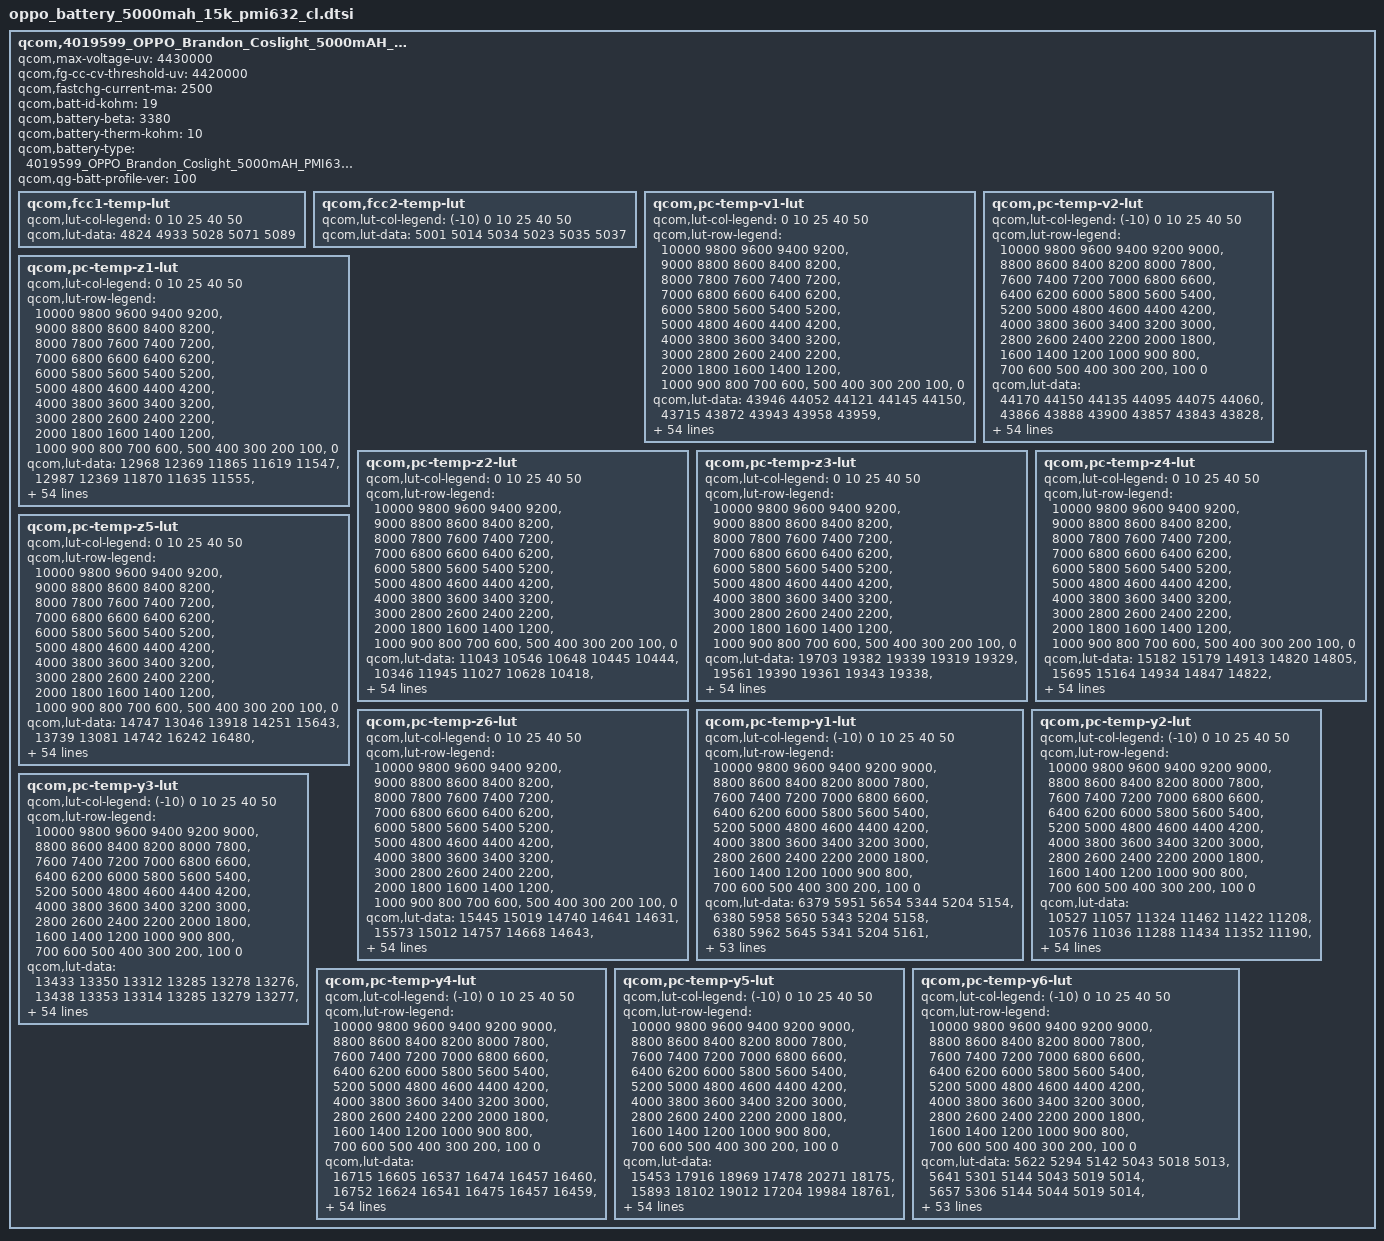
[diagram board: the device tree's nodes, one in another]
qcom,4019599_OPPO_Brandon_Coslight_5000mAH_PMI632 {
    /* 4019599_OPPO_Brandon_Coslight_5000mAH_PMI632_averaged_MasterSlave_Jun21th2019 */
    qcom,max-voltage-uv = <4430000>;
    qcom,fg-cc-cv-threshold-uv = <4420000>;
    qcom,fastchg-current-ma = <2500>;
    qcom,batt-id-kohm = <19>;
    qcom,battery-beta = <3380>;
    qcom,battery-therm-kohm = <10>;
    qcom,battery-type = "4019599_OPPO_Brandon_Coslight_5000mAH_PMI632_averaged_MasterSlave_Jun21th2019";
    qcom,qg-batt-profile-ver = <100>;

	qcom,fcc1-temp-lut {
		qcom,lut-col-legend = <0 10 25 40 50>;
		qcom,lut-data = <4824 4933 5028 5071 5089>;
	};

	qcom,fcc2-temp-lut {
		qcom,lut-col-legend = <(-10) 0 10 25 40 50>;
		qcom,lut-data = <5001 5014 5034 5023 5035 5037>;
	};

	qcom,pc-temp-v1-lut {
		qcom,lut-col-legend = <0 10 25 40 50>;
		qcom,lut-row-legend = <10000 9800 9600 9400 9200>,
			<9000 8800 8600 8400 8200>,
			<8000 7800 7600 7400 7200>,
			<7000 6800 6600 6400 6200>,
			<6000 5800 5600 5400 5200>,
			<5000 4800 4600 4400 4200>,
			<4000 3800 3600 3400 3200>,
			<3000 2800 2600 2400 2200>,
			<2000 1800 1600 1400 1200>,
			<1000 900 800 700 600>,
			<500 400 300 200 100>,
			<0>;
		qcom,lut-data = <43946 44052 44121 44145 44150>,
			<43715 43872 43943 43958 43959>,
			<43484 43673 43752 43763 43765>,
			<43250 43452 43548 43560 43565>,
			<43015 43216 43324 43348 43354>,
			<42775 42973 43088 43129 43132>,
			<42537 42718 42849 42899 42904>,
			<42298 42468 42605 42658 42669>,
			<42062 42232 42362 42413 42431>,
			<41833 42001 42123 42174 42194>,
			<41609 41771 41888 41938 41957>,
			<41391 41540 41655 41705 41722>,
			<41177 41317 41426 41475 41491>,
			<40969 41107 41204 41250 41263>,
			<40760 40903 40987 41033 41042>,
			<40548 40699 40778 40823 40827>,
			<40345 40492 40580 40620 40622>,
			<40167 40294 40389 40425 40426>,
			<40006 40115 40203 40234 40237>,
			<39846 39944 40027 40055 40059>,
			<39680 39762 39839 39875 39884>,
			<39513 39564 39583 39652 39672>,
			<39348 39362 39287 39374 39403>,
			<39181 39143 39087 39151 39172>,
			<39019 38923 38965 39011 39020>,
			<38857 38775 38862 38897 38896>,
			<38704 38684 38756 38778 38775>,
			<38593 38609 38654 38661 38661>,
			<38516 38532 38558 38556 38557>,
			<38453 38460 38465 38461 38460>,
			<38398 38394 38382 38375 38371>,
			<38350 38331 38308 38297 38290>,
			<38307 38275 38242 38225 38216>,
			<38269 38225 38182 38158 38145>,
			<38234 38181 38131 38096 38073>,
			<38198 38138 38081 38036 38002>,
			<38163 38097 38032 37975 37933>,
			<38120 38051 37983 37915 37863>,
			<38052 37984 37915 37840 37781>,
			<37961 37888 37820 37742 37680>,
			<37858 37780 37710 37630 37567>,
			<37736 37659 37591 37510 37443>,
			<37595 37521 37456 37376 37306>,
			<37427 37356 37298 37220 37149>,
			<37289 37220 37160 37092 37027>,
			<37195 37130 37070 37011 36954>,
			<37171 37106 37048 36984 36930>,
			<37137 37083 37027 36969 36911>,
			<37101 37053 37006 36940 36878>,
			<37019 36969 36905 36825 36734>,
			<36720 36657 36579 36489 36394>,
			<36255 36195 36124 36023 35934>,
			<35654 35595 35529 35431 35343>,
			<34825 34767 34715 34627 34529>,
			<33466 33434 33438 33348 33254>,
			<30000 30000 30000 30000 30000>;
	};

	qcom,pc-temp-v2-lut {
		qcom,lut-col-legend = <(-10) 0 10 25 40 50>;
		qcom,lut-row-legend = <10000 9800 9600 9400 9200 9000>,
			<8800 8600 8400 8200 8000 7800>,
			<7600 7400 7200 7000 6800 6600>,
			<6400 6200 6000 5800 5600 5400>,
			<5200 5000 4800 4600 4400 4200>,
			<4000 3800 3600 3400 3200 3000>,
			<2800 2600 2400 2200 2000 1800>,
			<1600 1400 1200 1000 900 800>,
			<700 600 500 400 300 200>,
			<100 0>;
		qcom,lut-data = <44170 44150 44135 44095 44075 44060>,
			<43866 43888 43900 43857 43843 43828>,
			<43585 43635 43668 43623 43613 43600>,
			<43329 43394 43441 43394 43388 43375>,
			<43100 43167 43219 43170 43167 43156>,
			<42872 42937 42991 42942 42942 42932>,
			<42631 42698 42753 42704 42706 42698>,
			<42387 42456 42510 42463 42466 42459>,
			<42143 42215 42269 42224 42227 42221>,
			<41901 41975 42028 41986 41988 41983>,
			<41652 41740 41791 41752 41753 41749>,
			<41381 41513 41557 41519 41520 41517>,
			<41110 41291 41326 41291 41292 41289>,
			<40889 41066 41102 41069 41071 41067>,
			<40712 40843 40883 40852 40854 40849>,
			<40512 40613 40666 40642 40645 40639>,
			<40219 40364 40451 40439 40442 40437>,
			<39897 40111 40233 40241 40244 40243>,
			<39663 39874 39997 40046 40057 40058>,
			<39489 39648 39746 39856 39879 39882>,
			<39321 39437 39513 39650 39681 39685>,
			<39140 39243 39306 39398 39425 39428>,
			<38960 39063 39117 39145 39170 39171>,
			<38793 38900 38950 38958 38982 38986>,
			<38636 38752 38798 38806 38830 38836>,
			<38486 38616 38662 38674 38695 38703>,
			<38333 38490 38539 38554 38573 38581>,
			<38193 38373 38427 38446 38463 38470>,
			<38097 38255 38324 38345 38363 38367>,
			<38029 38140 38227 38251 38271 38270>,
			<37968 38040 38136 38164 38187 38184>,
			<37909 37958 38050 38085 38112 38109>,
			<37853 37889 37970 38011 38039 38035>,
			<37794 37834 37892 37940 37963 37956>,
			<37733 37790 37817 37872 37884 37873>,
			<37669 37746 37753 37798 37796 37777>,
			<37600 37700 37703 37715 37688 37657>,
			<37527 37650 37653 37627 37578 37537>,
			<37448 37588 37588 37544 37484 37439>,
			<37361 37513 37512 37463 37396 37352>,
			<37273 37418 37425 37375 37305 37259>,
			<37185 37280 37320 37274 37212 37161>,
			<37099 37136 37197 37161 37102 37048>,
			<37016 37009 37051 37028 36966 36912>,
			<36925 36903 36933 36913 36866 36811>,
			<36821 36822 36861 36867 36828 36782>,
			<36759 36778 36836 36852 36813 36767>,
			<36687 36730 36806 36829 36796 36746>,
			<36584 36650 36754 36789 36753 36695>,
			<36439 36513 36630 36666 36585 36503>,
			<36212 36253 36329 36331 36211 36113>,
			<35837 35807 35826 35823 35695 35590>,
			<35270 35191 35135 35171 35021 34905>,
			<34453 34314 34209 34274 34083 33956>,
			<33093 32831 32728 32846 32678 32536>,
			<29714 27670 27572 27625 27714 27673>;
	};

	qcom,pc-temp-z1-lut {
		qcom,lut-col-legend = <0 10 25 40 50>;
		qcom,lut-row-legend = <10000 9800 9600 9400 9200>,
			<9000 8800 8600 8400 8200>,
			<8000 7800 7600 7400 7200>,
			<7000 6800 6600 6400 6200>,
			<6000 5800 5600 5400 5200>,
			<5000 4800 4600 4400 4200>,
			<4000 3800 3600 3400 3200>,
			<3000 2800 2600 2400 2200>,
			<2000 1800 1600 1400 1200>,
			<1000 900 800 700 600>,
			<500 400 300 200 100>,
			<0>;
		qcom,lut-data = <12968 12369 11865 11619 11547>,
			<12987 12369 11870 11635 11555>,
			<12980 12366 11871 11632 11555>,
			<12970 12360 11870 11630 11555>,
			<12959 12352 11862 11628 11554>,
			<12941 12341 11853 11627 11554>,
			<12928 12326 11846 11626 11554>,
			<12923 12310 11839 11624 11555>,
			<12917 12295 11834 11623 11558>,
			<12905 12281 11831 11624 11561>,
			<12872 12270 11829 11627 11565>,
			<12844 12262 11828 11628 11567>,
			<12835 12257 11827 11627 11566>,
			<12829 12255 11826 11626 11565>,
			<12822 12252 11825 11625 11565>,
			<12799 12249 11825 11625 11565>,
			<12775 12244 11825 11624 11565>,
			<12770 12241 11827 11625 11565>,
			<12768 12242 11829 11625 11566>,
			<12768 12245 11831 11625 11566>,
			<12774 12247 11833 11625 11567>,
			<12783 12248 11834 11626 11567>,
			<12787 12250 11836 11628 11567>,
			<12790 12253 11838 11630 11568>,
			<12792 12258 11842 11632 11569>,
			<12801 12262 11846 11634 11572>,
			<12816 12265 11850 11637 11575>,
			<12820 12268 11855 11640 11578>,
			<12813 12273 11859 11643 11582>,
			<12807 12278 11863 11646 11584>,
			<12813 12284 11867 11649 11585>,
			<12827 12291 11872 11652 11588>,
			<12834 12298 11878 11656 11591>,
			<12831 12303 11883 11659 11594>,
			<12827 12306 11888 11663 11597>,
			<12830 12310 11893 11667 11600>,
			<12837 12314 11898 11670 11603>,
			<12846 12319 11904 11673 11606>,
			<12862 12326 11909 11676 11608>,
			<12880 12336 11913 11680 11611>,
			<12890 12346 11918 11683 11614>,
			<12899 12354 11923 11687 11617>,
			<12905 12362 11930 11690 11620>,
			<12914 12369 11939 11693 11621>,
			<12928 12384 11948 11697 11623>,
			<12938 12392 11952 11699 11624>,
			<12936 12381 11956 11700 11625>,
			<12934 12390 11955 11700 11626>,
			<12925 12390 11964 11704 11629>,
			<12948 12411 11965 11708 11631>,
			<12981 12410 11977 11712 11635>,
			<12976 12423 11982 11719 11641>,
			<12970 12448 11997 11728 11649>,
			<13013 12475 12016 11742 11661>,
			<13013 12475 12016 11742 11661>,
			<13013 12475 12016 11742 11661>;
	};

	qcom,pc-temp-z2-lut {
		qcom,lut-col-legend = <0 10 25 40 50>;
		qcom,lut-row-legend = <10000 9800 9600 9400 9200>,
			<9000 8800 8600 8400 8200>,
			<8000 7800 7600 7400 7200>,
			<7000 6800 6600 6400 6200>,
			<6000 5800 5600 5400 5200>,
			<5000 4800 4600 4400 4200>,
			<4000 3800 3600 3400 3200>,
			<3000 2800 2600 2400 2200>,
			<2000 1800 1600 1400 1200>,
			<1000 900 800 700 600>,
			<500 400 300 200 100>,
			<0>;
		qcom,lut-data = <11043 10546 10648 10445 10444>,
			<10346 11945 11027 10628 10418>,
			<10349 12454 11980 10634 10484>,
			<10352 12098 12380 10641 10576>,
			<10347 11505 12147 11047 10589>,
			<10328 11057 11804 11998 10572>,
			<10312 10637 11506 12224 10551>,
			<10306 10441 11162 11325 10508>,
			<10302 10513 11020 10549 10456>,
			<10313 10619 11161 10701 10405>,
			<10385 10605 11345 11094 10332>,
			<10437 10477 11401 11329 10301>,
			<10391 10398 11449 11832 10302>,
			<10299 10579 11503 12180 10308>,
			<10262 10880 11584 12140 10312>,
			<10255 10914 11643 12067 10318>,
			<10250 10678 11632 12072 10328>,
			<10314 10499 11578 12194 10356>,
			<10534 10503 11471 12274 10386>,
			<10653 10519 11049 11634 10409>,
			<10531 10537 10685 10661 10434>,
			<10357 10562 10694 10512 10462>,
			<10325 10584 10749 10599 10492>,
			<10344 10596 10762 10649 10523>,
			<10368 10605 10705 10618 10686>,
			<10388 10606 10654 10578 10907>,
			<10407 10592 10672 10612 10919>,
			<10414 10578 10716 10757 10773>,
			<10414 10579 10734 10825 10648>,
			<10413 10581 10740 10736 10543>,
			<10414 10583 10742 10613 10439>,
			<10417 10582 10728 10552 10388>,
			<10420 10582 10699 10507 10350>,
			<10423 10585 10694 10496 10338>,
			<10427 10593 10717 10543 10363>,
			<10429 10596 10746 10607 10406>,
			<10430 10600 10769 10652 10465>,
			<10432 10606 10793 10696 10557>,
			<10438 10614 10812 10734 10625>,
			<10446 10631 10829 10826 10668>,
			<10448 10638 10841 10901 10712>,
			<10446 10627 10847 10900 10786>,
			<10446 10619 10849 10889 10861>,
			<10466 10632 10854 10885 10877>,
			<10690 10731 10866 10822 10801>,
			<10709 10785 10893 10723 10604>,
			<10704 10809 10835 10696 10623>,
			<10694 10820 10810 10702 10643>,
			<10640 10972 10815 10803 10727>,
			<10683 11011 10892 10825 10696>,
			<10558 10879 10869 10623 10424>,
			<10392 10853 10839 10482 10331>,
			<10188 10697 10793 10416 10271>,
			<9984 10462 10693 11606 10223>,
			<9984 10462 10693 11606 10223>,
			<9984 10462 10693 11606 10223>;
	};

	qcom,pc-temp-z3-lut {
		qcom,lut-col-legend = <0 10 25 40 50>;
		qcom,lut-row-legend = <10000 9800 9600 9400 9200>,
			<9000 8800 8600 8400 8200>,
			<8000 7800 7600 7400 7200>,
			<7000 6800 6600 6400 6200>,
			<6000 5800 5600 5400 5200>,
			<5000 4800 4600 4400 4200>,
			<4000 3800 3600 3400 3200>,
			<3000 2800 2600 2400 2200>,
			<2000 1800 1600 1400 1200>,
			<1000 900 800 700 600>,
			<500 400 300 200 100>,
			<0>;
		qcom,lut-data = <19703 19382 19339 19319 19329>,
			<19561 19390 19361 19343 19338>,
			<19607 19406 19374 19358 19353>,
			<19663 19446 19389 19374 19364>,
			<19676 19495 19417 19390 19372>,
			<19680 19519 19440 19406 19379>,
			<19683 19534 19446 19410 19382>,
			<19685 19543 19445 19402 19383>,
			<19687 19547 19447 19394 19384>,
			<19691 19547 19458 19397 19383>,
			<19706 19541 19469 19405 19380>,
			<19716 19525 19469 19409 19376>,
			<19702 19515 19464 19414 19374>,
			<19674 19527 19459 19417 19372>,
			<19664 19547 19455 19411 19369>,
			<19664 19547 19450 19403 19367>,
			<19666 19513 19443 19397 19364>,
			<19670 19487 19435 19394 19360>,
			<19682 19487 19425 19390 19355>,
			<19688 19489 19409 19374 19350>,
			<19670 19491 19397 19356 19345>,
			<19645 19499 19402 19353 19344>,
			<19641 19508 19416 19357 19344>,
			<19644 19512 19419 19359 19345>,
			<19649 19516 19402 19349 19356>,
			<19653 19517 19387 19337 19372>,
			<19658 19509 19387 19346 19378>,
			<19659 19500 19390 19381 19389>,
			<19653 19499 19395 19398 19394>,
			<19645 19498 19409 19395 19388>,
			<19639 19498 19419 19388 19379>,
			<19634 19499 19419 19383 19371>,
			<19630 19501 19418 19376 19363>,
			<19626 19500 19416 19370 19357>,
			<19624 19498 19412 19364 19352>,
			<19620 19496 19407 19358 19348>,
			<19617 19494 19403 19355 19345>,
			<19613 19491 19399 19352 19342>,
			<19609 19487 19397 19351 19342>,
			<19605 19483 19395 19352 19342>,
			<19598 19479 19393 19352 19342>,
			<19588 19475 19391 19354 19346>,
			<19577 19471 19389 19356 19352>,
			<19566 19465 19385 19356 19354>,
			<19495 19439 19376 19350 19349>,
			<19442 19419 19369 19337 19334>,
			<19330 19390 19361 19336 19325>,
			<19320 19347 19360 19327 19322>,
			<19312 19327 19344 19324 19317>,
			<19303 19324 19340 19327 19329>,
			<19321 19330 19353 19350 19345>,
			<19322 19327 19341 19350 19346>,
			<19334 19324 19343 19346 19342>,
			<19341 19322 19343 19261 19343>,
			<19341 19322 19343 19261 19343>,
			<19341 19322 19343 19261 19343>;
	};

	qcom,pc-temp-z4-lut {
		qcom,lut-col-legend = <0 10 25 40 50>;
		qcom,lut-row-legend = <10000 9800 9600 9400 9200>,
			<9000 8800 8600 8400 8200>,
			<8000 7800 7600 7400 7200>,
			<7000 6800 6600 6400 6200>,
			<6000 5800 5600 5400 5200>,
			<5000 4800 4600 4400 4200>,
			<4000 3800 3600 3400 3200>,
			<3000 2800 2600 2400 2200>,
			<2000 1800 1600 1400 1200>,
			<1000 900 800 700 600>,
			<500 400 300 200 100>,
			<0>;
		qcom,lut-data = <15182 15179 14913 14820 14805>,
			<15695 15164 14934 14847 14822>,
			<15608 15134 14904 14840 14816>,
			<15472 15068 14871 14826 14806>,
			<15365 14986 14829 14796 14794>,
			<15267 14938 14789 14749 14777>,
			<15181 14905 14770 14734 14762>,
			<15114 14873 14755 14737 14749>,
			<15054 14832 14741 14739 14736>,
			<14993 14795 14709 14725 14723>,
			<14922 14783 14676 14692 14711>,
			<14876 14782 14661 14672 14703>,
			<14867 14777 14651 14651 14698>,
			<14865 14738 14646 14639 14694>,
			<14858 14684 14642 14639 14690>,
			<14844 14678 14641 14639 14686>,
			<14824 14716 14641 14639 14683>,
			<14790 14744 14643 14636 14680>,
			<14734 14737 14647 14634 14678>,
			<14707 14722 14662 14645 14679>,
			<14724 14719 14684 14670 14680>,
			<14752 14726 14726 14707 14691>,
			<14767 14738 14786 14769 14753>,
			<14774 14767 14807 14801 14795>,
			<14783 14811 14809 14802 14778>,
			<14802 14824 14811 14803 14750>,
			<14826 14817 14804 14790 14733>,
			<14833 14807 14785 14739 14709>,
			<14832 14797 14765 14707 14694>,
			<14831 14785 14741 14700 14691>,
			<14828 14774 14722 14695 14689>,
			<14821 14764 14714 14692 14686>,
			<14813 14756 14709 14688 14683>,
			<14804 14749 14707 14687 14681>,
			<14796 14744 14705 14688 14681>,
			<14787 14740 14705 14688 14681>,
			<14778 14736 14705 14689 14681>,
			<14769 14734 14706 14689 14683>,
			<14761 14732 14708 14691 14685>,
			<14753 14731 14712 14697 14692>,
			<14745 14729 14714 14702 14698>,
			<14738 14719 14709 14697 14692>,
			<14727 14706 14698 14689 14683>,
			<14711 14696 14693 14688 14683>,
			<14697 14674 14675 14681 14677>,
			<14733 14663 14654 14663 14661>,
			<14853 14684 14650 14655 14658>,
			<14861 14727 14642 14647 14644>,
			<14864 14742 14647 14634 14629>,
			<14861 14741 14653 14636 14632>,
			<14848 14747 14659 14644 14648>,
			<14863 14757 14677 14650 14653>,
			<14863 14768 14675 14655 14659>,
			<14878 14783 14679 14746 14657>,
			<14878 14783 14679 14746 14657>,
			<14878 14783 14679 14746 14657>;
	};

	qcom,pc-temp-z5-lut {
		qcom,lut-col-legend = <0 10 25 40 50>;
		qcom,lut-row-legend = <10000 9800 9600 9400 9200>,
			<9000 8800 8600 8400 8200>,
			<8000 7800 7600 7400 7200>,
			<7000 6800 6600 6400 6200>,
			<6000 5800 5600 5400 5200>,
			<5000 4800 4600 4400 4200>,
			<4000 3800 3600 3400 3200>,
			<3000 2800 2600 2400 2200>,
			<2000 1800 1600 1400 1200>,
			<1000 900 800 700 600>,
			<500 400 300 200 100>,
			<0>;
		qcom,lut-data = <14747 13046 13918 14251 15643>,
			<13739 13081 14742 16242 16480>,
			<14343 13234 15031 17518 18075>,
			<15181 13918 15551 18938 19444>,
			<15594 15096 17205 20465 20449>,
			<15831 16409 19129 22101 21269>,
			<16112 18109 20216 22520 21866>,
			<16535 19401 21159 22062 22257>,
			<17094 20261 22461 21669 22601>,
			<17928 20930 25995 23588 23059>,
			<19476 20968 30452 28286 23594>,
			<20581 20578 34018 32056 24063>,
			<20433 20548 37307 38700 24546>,
			<19907 25177 39480 43009 25081>,
			<19913 32451 41064 41381 25842>,
			<20941 33192 41956 38515 26787>,
			<22642 27204 40945 38143 27209>,
			<25393 22670 37677 39571 27272>,
			<29891 23320 34232 40498 27217>,
			<32107 25281 29871 34881 26844>,
			<31676 28204 26887 26279 26064>,
			<31030 34370 29931 24629 25179>,
			<31614 39414 37294 24605 23548>,
			<36109 40714 38899 24456 22133>,
			<40913 41472 29877 21106 21934>,
			<44042 41201 21606 16862 22293>,
			<46601 35906 20807 17654 22957>,
			<47039 30746 20478 22713 25895>,
			<44078 30020 20727 25786 27583>,
			<40407 29720 23948 26609 27546>,
			<38406 29733 27880 27184 27490>,
			<36856 31258 30653 27614 27341>,
			<36178 33344 33109 28200 26979>,
			<36028 34801 34710 28570 26884>,
			<35966 36165 35959 28873 27574>,
			<36053 37192 36581 29142 28396>,
			<36444 38011 36179 29228 28673>,
			<37025 38571 35176 29132 28804>,
			<38260 38621 34125 28828 28670>,
			<39831 38271 32729 27772 26890>,
			<39815 37826 31745 26812 25241>,
			<36187 36946 31528 27037 26564>,
			<34724 36205 31335 27649 29243>,
			<35787 36404 30143 27777 30159>,
			<29211 34744 31201 26716 29293>,
			<22775 30477 33608 24077 23600>,
			<12679 20312 29073 24696 20833>,
			<12408 14903 30020 23109 22284>,
			<12217 13751 22940 26366 26202>,
			<12124 13783 20885 25791 37630>,
			<12577 14052 21736 28003 27786>,
			<12385 13576 17557 24368 24075>,
			<12447 13207 17223 20864 20207>,
			<12307 12896 16508 11789 18636>,
			<12307 12896 16508 11789 18636>,
			<12307 12896 16508 11789 18636>;
	};

	qcom,pc-temp-z6-lut {
		qcom,lut-col-legend = <0 10 25 40 50>;
		qcom,lut-row-legend = <10000 9800 9600 9400 9200>,
			<9000 8800 8600 8400 8200>,
			<8000 7800 7600 7400 7200>,
			<7000 6800 6600 6400 6200>,
			<6000 5800 5600 5400 5200>,
			<5000 4800 4600 4400 4200>,
			<4000 3800 3600 3400 3200>,
			<3000 2800 2600 2400 2200>,
			<2000 1800 1600 1400 1200>,
			<1000 900 800 700 600>,
			<500 400 300 200 100>,
			<0>;
		qcom,lut-data = <15445 15019 14740 14641 14631>,
			<15573 15012 14757 14668 14643>,
			<15540 15002 14753 14672 14649>,
			<15487 14987 14748 14676 14652>,
			<15437 14969 14743 14673 14651>,
			<15382 14954 14737 14664 14648>,
			<15333 14940 14730 14658 14644>,
			<15294 14926 14722 14655 14640>,
			<15259 14907 14714 14651 14635>,
			<15229 14888 14706 14645 14629>,
			<15202 14874 14699 14638 14623>,
			<15178 14863 14691 14633 14618>,
			<15157 14852 14685 14628 14615>,
			<15138 14841 14679 14623 14611>,
			<15122 14830 14675 14619 14608>,
			<15110 14824 14672 14615 14605>,
			<15099 14821 14668 14611 14601>,
			<15085 14819 14664 14607 14598>,
			<15067 14815 14662 14605 14594>,
			<15059 14811 14662 14604 14592>,
			<15060 14811 14662 14603 14589>,
			<15060 14818 14678 14610 14593>,
			<15062 14829 14714 14640 14620>,
			<15069 14846 14726 14657 14639>,
			<15078 14867 14721 14654 14638>,
			<15091 14873 14714 14650 14635>,
			<15106 14868 14709 14646 14633>,
			<15110 14861 14705 14644 14629>,
			<15108 14856 14701 14641 14625>,
			<15104 14852 14699 14637 14621>,
			<15101 14849 14696 14632 14616>,
			<15097 14847 14694 14628 14611>,
			<15093 14845 14691 14623 14606>,
			<15090 14843 14689 14620 14602>,
			<15087 14842 14688 14617 14598>,
			<15084 14841 14686 14615 14596>,
			<15082 14840 14685 14613 14595>,
			<15081 14839 14684 14612 14594>,
			<15081 14839 14684 14612 14594>,
			<15081 14840 14686 14615 14597>,
			<15081 14839 14687 14618 14600>,
			<15079 14837 14685 14617 14600>,
			<15077 14833 14681 14615 14600>,
			<15074 14830 14678 14615 14601>,
			<15049 14815 14669 14610 14596>,
			<15041 14804 14657 14595 14581>,
			<15036 14799 14652 14592 14576>,
			<15035 14796 14648 14583 14568>,
			<15034 14795 14643 14576 14558>,
			<15035 14796 14645 14579 14566>,
			<15045 14807 14657 14596 14583>,
			<15061 14814 14660 14600 14588>,
			<15078 14826 14665 14603 14591>,
			<15107 14845 14671 14605 14594>,
			<15107 14845 14671 14605 14594>,
			<15107 14845 14671 14605 14594>;
	};

	qcom,pc-temp-y1-lut {
		qcom,lut-col-legend = <(-10) 0 10 25 40 50>;
		qcom,lut-row-legend = <10000 9800 9600 9400 9200 9000>,
			<8800 8600 8400 8200 8000 7800>,
			<7600 7400 7200 7000 6800 6600>,
			<6400 6200 6000 5800 5600 5400>,
			<5200 5000 4800 4600 4400 4200>,
			<4000 3800 3600 3400 3200 3000>,
			<2800 2600 2400 2200 2000 1800>,
			<1600 1400 1200 1000 900 800>,
			<700 600 500 400 300 200>,
			<100 0>;
		qcom,lut-data = <6379 5951 5654 5344 5204 5154>,
			<6380 5958 5650 5343 5204 5158>,
			<6380 5962 5645 5341 5204 5161>,
			<6380 5963 5641 5339 5203 5162>,
			<6380 5962 5636 5338 5203 5163>,
			<6379 5960 5631 5337 5202 5162>,
			<6377 5954 5625 5334 5200 5161>,
			<6373 5947 5620 5331 5199 5158>,
			<6376 5945 5617 5329 5197 5157>,
			<6394 5940 5615 5328 5196 5156>,
			<6405 5938 5613 5326 5195 5155>,
			<6396 5938 5609 5325 5193 5155>,
			<6381 5939 5605 5324 5191 5155>,
			<6379 5940 5603 5324 5191 5156>,
			<6387 5945 5603 5324 5192 5157>,
			<6394 5948 5602 5324 5193 5157>,
			<6402 5947 5603 5324 5193 5156>,
			<6408 5946 5604 5323 5194 5155>,
			<6408 5947 5605 5323 5194 5155>,
			<6403 5950 5604 5324 5194 5155>,
			<6400 5951 5604 5325 5194 5155>,
			<6403 5948 5603 5327 5195 5156>,
			<6408 5942 5601 5329 5196 5156>,
			<6404 5943 5601 5331 5196 5157>,
			<6387 5950 5603 5334 5197 5158>,
			<6377 5955 5605 5337 5198 5159>,
			<6398 5956 5611 5339 5200 5160>,
			<6429 5957 5618 5342 5203 5161>,
			<6432 5956 5621 5345 5207 5163>,
			<6415 5952 5624 5348 5211 5165>,
			<6399 5951 5626 5351 5214 5167>,
			<6384 5955 5628 5355 5215 5170>,
			<6370 5960 5630 5358 5215 5172>,
			<6367 5962 5632 5362 5217 5173>,
			<6369 5961 5634 5367 5219 5175>,
			<6371 5960 5636 5371 5222 5176>,
			<6374 5960 5643 5373 5223 5178>,
			<6379 5959 5649 5375 5224 5181>,
			<6380 5959 5648 5377 5226 5182>,
			<6382 5959 5645 5379 5227 5182>,
			<6384 5958 5644 5380 5228 5183>,
			<6377 5955 5652 5383 5230 5185>,
			<6368 5951 5657 5386 5232 5186>,
			<6367 5947 5662 5389 5234 5188>,
			<6363 5961 5674 5394 5237 5190>,
			<6373 5966 5671 5399 5238 5192>,
			<6380 5972 5671 5399 5238 5191>,
			<6373 5979 5674 5400 5237 5189>,
			<6389 5970 5680 5401 5238 5190>,
			<6418 5979 5674 5400 5239 5191>,
			<6421 5977 5688 5401 5243 5194>,
			<6487 5988 5694 5410 5246 5198>,
			<6519 5989 5718 5424 5251 5204>,
			<6613 6062 5713 5441 5261 5212>,
			<6613 6062 5713 5441 5261 5212>,
			<6613 6062 5713 5441 5261 5212>;
	};

	qcom,pc-temp-y2-lut {
		qcom,lut-col-legend = <(-10) 0 10 25 40 50>;
		qcom,lut-row-legend = <10000 9800 9600 9400 9200 9000>,
			<8800 8600 8400 8200 8000 7800>,
			<7600 7400 7200 7000 6800 6600>,
			<6400 6200 6000 5800 5600 5400>,
			<5200 5000 4800 4600 4400 4200>,
			<4000 3800 3600 3400 3200 3000>,
			<2800 2600 2400 2200 2000 1800>,
			<1600 1400 1200 1000 900 800>,
			<700 600 500 400 300 200>,
			<100 0>;
		qcom,lut-data = <10527 11057 11324 11462 11422 11208>,
			<10576 11036 11288 11434 11352 11190>,
			<10628 11013 11252 11403 11268 11165>,
			<10677 10992 11216 11369 11186 11136>,
			<10718 10976 11182 11333 11121 11104>,
			<10748 10970 11153 11296 11088 11072>,
			<10768 10972 11121 11245 11085 11031>,
			<10783 10978 11095 11200 11087 10993>,
			<10790 10983 11090 11198 11075 10984>,
			<10795 10989 11094 11219 11041 10991>,
			<10801 10998 11101 11233 11013 10993>,
			<10837 11010 11119 11225 10998 10972>,
			<10893 11028 11145 11214 10988 10947>,
			<10926 11057 11163 11219 11010 10940>,
			<10951 11110 11177 11236 11107 10936>,
			<10963 11138 11197 11260 11166 10936>,
			<10961 11131 11257 11293 11166 10949>,
			<10958 11119 11320 11338 11163 10975>,
			<10963 11124 11332 11401 11216 11047>,
			<10986 11154 11331 11494 11378 11210>,
			<11000 11179 11330 11536 11454 11284>,
			<10995 11190 11336 11508 11410 11254>,
			<10983 11199 11344 11473 11358 11219>,
			<10968 11203 11351 11472 11351 11221>,
			<10945 11205 11360 11497 11353 11242>,
			<10911 11207 11372 11519 11358 11267>,
			<10712 11211 11390 11558 11381 11292>,
			<10411 11215 11406 11602 11416 11326>,
			<10239 11213 11411 11616 11468 11378>,
			<9930 11204 11415 11621 11550 11457>,
			<9741 11195 11416 11628 11620 11537>,
			<9717 11190 11413 11646 11689 11615>,
			<9702 11185 11408 11661 11742 11693>,
			<9692 11170 11401 11655 11758 11772>,
			<9684 11135 11386 11629 11758 11849>,
			<9678 11094 11371 11612 11725 11866>,
			<9674 11053 11354 11586 11612 11756>,
			<9671 11005 11333 11556 11505 11610>,
			<9669 10953 11307 11546 11491 11504>,
			<9667 10896 11274 11540 11514 11399>,
			<9665 10785 11235 11537 11527 11360>,
			<9664 10190 11181 11519 11537 11369>,
			<9663 9766 11109 11511 11523 11377>,
			<9662 9721 11005 11504 11406 11401>,
			<9661 9694 10936 11404 11340 11191>,
			<9660 9688 10905 11414 11193 11067>,
			<9659 9681 10868 11402 11201 11033>,
			<9658 9674 10823 11377 11267 11074>,
			<9657 9670 10800 11384 11316 11125>,
			<9655 9667 10750 11418 11234 11070>,
			<9653 9663 10630 11380 11182 10978>,
			<9651 9659 10285 11271 11076 10891>,
			<9649 9654 9774 11170 10949 10784>,
			<9649 9651 9667 11067 10836 10610>,
			<9649 9651 9667 11067 10836 10610>,
			<9649 9651 9667 11067 10836 10610>;
	};

	qcom,pc-temp-y3-lut {
		qcom,lut-col-legend = <(-10) 0 10 25 40 50>;
		qcom,lut-row-legend = <10000 9800 9600 9400 9200 9000>,
			<8800 8600 8400 8200 8000 7800>,
			<7600 7400 7200 7000 6800 6600>,
			<6400 6200 6000 5800 5600 5400>,
			<5200 5000 4800 4600 4400 4200>,
			<4000 3800 3600 3400 3200 3000>,
			<2800 2600 2400 2200 2000 1800>,
			<1600 1400 1200 1000 900 800>,
			<700 600 500 400 300 200>,
			<100 0>;
		qcom,lut-data = <13433 13350 13312 13285 13278 13276>,
			<13438 13353 13314 13285 13279 13277>,
			<13445 13358 13317 13285 13280 13277>,
			<13453 13363 13319 13286 13281 13278>,
			<13460 13367 13321 13286 13281 13279>,
			<13462 13369 13323 13287 13282 13279>,
			<13462 13370 13323 13287 13282 13280>,
			<13461 13371 13324 13287 13282 13280>,
			<13460 13371 13324 13288 13282 13280>,
			<13457 13369 13325 13292 13283 13281>,
			<13453 13369 13325 13294 13284 13282>,
			<13446 13369 13325 13295 13284 13282>,
			<13438 13370 13324 13295 13284 13282>,
			<13431 13371 13324 13296 13285 13283>,
			<13426 13371 13325 13298 13288 13283>,
			<13421 13371 13327 13299 13289 13283>,
			<13414 13367 13328 13298 13289 13284>,
			<13407 13361 13329 13298 13289 13286>,
			<13405 13357 13327 13299 13290 13287>,
			<13404 13353 13322 13300 13291 13289>,
			<13403 13349 13318 13300 13292 13290>,
			<13400 13346 13315 13296 13288 13284>,
			<13396 13343 13312 13290 13282 13278>,
			<13393 13341 13310 13288 13280 13277>,
			<13390 13340 13308 13286 13279 13277>,
			<13387 13339 13307 13286 13279 13277>,
			<13375 13338 13307 13286 13278 13277>,
			<13361 13338 13307 13287 13277 13277>,
			<13360 13336 13307 13287 13277 13276>,
			<13368 13333 13307 13286 13278 13275>,
			<13377 13331 13307 13286 13278 13274>,
			<13387 13329 13308 13286 13278 13275>,
			<13400 13327 13308 13286 13278 13276>,
			<13417 13328 13307 13286 13278 13277>,
			<13438 13331 13306 13286 13278 13278>,
			<13465 13335 13305 13286 13278 13278>,
			<13501 13338 13307 13286 13277 13277>,
			<13545 13342 13309 13286 13276 13276>,
			<13596 13345 13310 13286 13276 13276>,
			<13658 13347 13310 13286 13277 13277>,
			<13729 13350 13311 13287 13277 13278>,
			<13808 13354 13313 13287 13280 13279>,
			<13901 13360 13314 13287 13281 13279>,
			<14018 13381 13314 13287 13278 13277>,
			<14152 13410 13317 13286 13279 13276>,
			<14173 13429 13316 13288 13282 13283>,
			<14277 13456 13320 13291 13285 13284>,
			<14412 13504 13325 13293 13288 13286>,
			<14588 13558 13332 13297 13289 13286>,
			<14855 13650 13340 13298 13286 13283>,
			<15496 13800 13345 13294 13284 13282>,
			<16963 14106 13357 13295 13285 13283>,
			<20587 15031 13414 13300 13288 13286>,
			<31097 18295 13708 13306 13295 13294>,
			<31097 18295 13708 13306 13295 13294>,
			<31097 18295 13708 13306 13295 13294>;
	};

	qcom,pc-temp-y4-lut {
		qcom,lut-col-legend = <(-10) 0 10 25 40 50>;
		qcom,lut-row-legend = <10000 9800 9600 9400 9200 9000>,
			<8800 8600 8400 8200 8000 7800>,
			<7600 7400 7200 7000 6800 6600>,
			<6400 6200 6000 5800 5600 5400>,
			<5200 5000 4800 4600 4400 4200>,
			<4000 3800 3600 3400 3200 3000>,
			<2800 2600 2400 2200 2000 1800>,
			<1600 1400 1200 1000 900 800>,
			<700 600 500 400 300 200>,
			<100 0>;
		qcom,lut-data = <16715 16605 16537 16474 16457 16460>,
			<16752 16624 16541 16475 16457 16459>,
			<16821 16648 16545 16476 16458 16459>,
			<16899 16673 16549 16478 16458 16459>,
			<16964 16694 16553 16479 16459 16459>,
			<16994 16705 16555 16481 16460 16459>,
			<16998 16709 16556 16484 16461 16460>,
			<17000 16712 16557 16487 16462 16460>,
			<17001 16717 16560 16488 16464 16461>,
			<17001 16725 16566 16488 16466 16462>,
			<17000 16734 16574 16487 16469 16463>,
			<16987 16745 16585 16491 16473 16465>,
			<16968 16757 16600 16499 16478 16469>,
			<16975 16763 16615 16507 16481 16473>,
			<17023 16769 16632 16515 16484 16477>,
			<17054 16771 16644 16525 16488 16482>,
			<16970 16755 16651 16543 16496 16488>,
			<16838 16725 16656 16563 16509 16494>,
			<16804 16695 16646 16578 16527 16507>,
			<16798 16661 16604 16592 16552 16528>,
			<16791 16635 16568 16597 16562 16536>,
			<16770 16618 16545 16554 16527 16511>,
			<16740 16605 16528 16494 16483 16478>,
			<16710 16595 16520 16479 16470 16468>,
			<16676 16587 16514 16474 16464 16463>,
			<16654 16579 16513 16472 16462 16462>,
			<16649 16573 16513 16473 16464 16463>,
			<16650 16567 16513 16475 16468 16464>,
			<16657 16556 16514 16478 16472 16467>,
			<16674 16540 16517 16484 16478 16475>,
			<16688 16531 16518 16490 16484 16482>,
			<16696 16529 16517 16498 16495 16491>,
			<16702 16529 16515 16504 16504 16498>,
			<16705 16532 16511 16506 16505 16500>,
			<16708 16543 16503 16508 16506 16502>,
			<16708 16556 16501 16508 16506 16502>,
			<16707 16571 16507 16494 16489 16487>,
			<16704 16587 16516 16477 16471 16473>,
			<16704 16599 16523 16473 16468 16472>,
			<16705 16609 16530 16472 16467 16472>,
			<16707 16616 16536 16472 16467 16472>,
			<16715 16623 16543 16478 16471 16475>,
			<16729 16626 16544 16481 16471 16474>,
			<16749 16618 16539 16475 16458 16455>,
			<16774 16626 16535 16471 16451 16450>,
			<16747 16627 16527 16473 16464 16471>,
			<16759 16648 16542 16487 16487 16498>,
			<16779 16675 16567 16508 16518 16531>,
			<16794 16712 16603 16538 16543 16551>,
			<16807 16744 16639 16539 16513 16506>,
			<16873 16757 16633 16498 16470 16470>,
			<17119 16762 16633 16489 16467 16468>,
			<17838 16848 16679 16504 16470 16469>,
			<21750 17815 16763 16531 16487 16487>,
			<21750 17815 16763 16531 16487 16487>,
			<21750 17815 16763 16531 16487 16487>;
	};

	qcom,pc-temp-y5-lut {
		qcom,lut-col-legend = <(-10) 0 10 25 40 50>;
		qcom,lut-row-legend = <10000 9800 9600 9400 9200 9000>,
			<8800 8600 8400 8200 8000 7800>,
			<7600 7400 7200 7000 6800 6600>,
			<6400 6200 6000 5800 5600 5400>,
			<5200 5000 4800 4600 4400 4200>,
			<4000 3800 3600 3400 3200 3000>,
			<2800 2600 2400 2200 2000 1800>,
			<1600 1400 1200 1000 900 800>,
			<700 600 500 400 300 200>,
			<100 0>;
		qcom,lut-data = <15453 17916 18969 17478 20271 18175>,
			<15893 18102 19012 17204 19984 18761>,
			<16321 18122 18957 16813 19658 19077>,
			<16724 18046 18822 16394 19307 19187>,
			<17094 17942 18622 16034 18941 19160>,
			<17418 17879 18375 15820 18574 19061>,
			<17744 17758 17923 15472 18060 18689>,
			<18014 17550 17336 15044 17481 18150>,
			<18099 17355 16883 15159 17111 17834>,
			<18135 17086 16500 16035 16861 17612>,
			<18139 16949 16166 16556 16584 17361>,
			<17488 17306 15816 16220 16104 17004>,
			<16501 17953 15552 15744 15674 16594>,
			<16677 18386 15622 15671 15756 16166>,
			<18532 18689 16163 15686 16300 15688>,
			<19720 19122 16986 15694 16580 15488>,
			<19387 20534 19048 15609 16065 15558>,
			<18869 22131 21309 15497 15420 15710>,
			<19000 22323 21998 16242 15631 16074>,
			<20243 22061 22339 19340 16821 16892>,
			<21331 21815 22438 21043 18025 17397>,
			<21807 21630 22165 21000 19269 17520>,
			<22163 21487 21741 20878 20220 17624>,
			<22451 21582 21289 20582 20230 18042>,
			<22807 22137 20595 19906 19890 18964>,
			<22990 22691 20323 19585 19426 19350>,
			<19931 23335 20868 20039 18342 18927>,
			<15127 23922 21661 20590 17345 18226>,
			<13738 23783 22219 20582 17298 17342>,
			<13316 22777 22838 20360 17446 16113>,
			<13164 21644 23485 20350 17639 15685>,
			<13221 20330 24656 20801 17915 16076>,
			<13341 19229 25631 21510 18287 16778>,
			<13466 19287 25288 22338 18893 17865>,
			<13614 20150 24105 23397 19861 19504>,
			<13785 21060 23618 24109 20674 20602>,
			<14042 21980 23996 24605 21474 21187>,
			<14285 22749 24385 24939 21993 21670>,
			<14284 22965 23977 24726 21640 22323>,
			<14058 23013 22961 23832 20740 23058>,
			<13815 22828 22410 22832 20571 23241>,
			<13596 18575 22014 21562 22093 22822>,
			<13475 15197 21482 20995 22564 22512>,
			<13746 14707 20428 21226 20765 22141>,
			<13897 14316 20434 19385 19847 17551>,
			<14055 14308 19970 19664 18428 18931>,
			<14290 14111 19823 19753 18102 17582>,
			<14568 14543 19419 19272 18150 16821>,
			<14709 14502 19331 19582 17884 16356>,
			<14995 15499 19786 20220 17599 16622>,
			<14439 16202 19656 20666 18449 17425>,
			<12149 15331 18125 21606 18655 17242>,
			<10383 13507 14828 21980 19370 17686>,
			<9286 10572 14180 23356 25137 25250>,
			<9286 10572 14180 23356 25137 25250>,
			<9286 10572 14180 23356 25137 25250>;
	};

	qcom,pc-temp-y6-lut {
		qcom,lut-col-legend = <(-10) 0 10 25 40 50>;
		qcom,lut-row-legend = <10000 9800 9600 9400 9200 9000>,
			<8800 8600 8400 8200 8000 7800>,
			<7600 7400 7200 7000 6800 6600>,
			<6400 6200 6000 5800 5600 5400>,
			<5200 5000 4800 4600 4400 4200>,
			<4000 3800 3600 3400 3200 3000>,
			<2800 2600 2400 2200 2000 1800>,
			<1600 1400 1200 1000 900 800>,
			<700 600 500 400 300 200>,
			<100 0>;
		qcom,lut-data = <5622 5294 5142 5043 5018 5013>,
			<5641 5301 5144 5043 5019 5014>,
			<5657 5306 5144 5044 5019 5014>,
			<5669 5310 5145 5045 5020 5015>,
			<5677 5313 5145 5045 5021 5016>,
			<5680 5314 5145 5046 5022 5016>,
			<5677 5313 5144 5047 5022 5017>,
			<5671 5310 5142 5047 5023 5017>,
			<5665 5309 5142 5048 5023 5017>,
			<5661 5308 5143 5050 5024 5018>,
			<5655 5307 5143 5052 5025 5019>,
			<5642 5308 5145 5054 5027 5020>,
			<5629 5310 5148 5056 5028 5021>,
			<5628 5311 5151 5058 5030 5023>,
			<5637 5311 5156 5061 5032 5024>,
			<5643 5310 5159 5065 5035 5026>,
			<5617 5303 5162 5070 5037 5028>,
			<5578 5291 5164 5075 5041 5031>,
			<5570 5280 5160 5080 5046 5036>,
			<5571 5268 5144 5085 5054 5043>,
			<5571 5259 5131 5086 5057 5046>,
			<5569 5252 5122 5071 5044 5034>,
			<5565 5247 5116 5050 5027 5019>,
			<5563 5245 5112 5044 5022 5016>,
			<5562 5244 5110 5042 5020 5015>,
			<5561 5244 5109 5041 5019 5014>,
			<5561 5245 5110 5042 5019 5014>,
			<5561 5246 5112 5043 5020 5015>,
			<5564 5246 5113 5045 5021 5015>,
			<5582 5244 5115 5046 5023 5017>,
			<5604 5243 5117 5048 5026 5018>,
			<5626 5246 5118 5051 5029 5021>,
			<5651 5251 5119 5054 5032 5024>,
			<5679 5259 5119 5055 5032 5026>,
			<5710 5271 5119 5056 5033 5027>,
			<5745 5285 5119 5057 5032 5027>,
			<5786 5302 5123 5053 5027 5022>,
			<5831 5322 5130 5048 5022 5017>,
			<5880 5345 5135 5048 5021 5018>,
			<5935 5370 5141 5049 5021 5019>,
			<5996 5396 5148 5049 5022 5020>,
			<6067 5417 5157 5052 5025 5021>,
			<6150 5442 5165 5053 5026 5021>,
			<6250 5480 5172 5052 5020 5014>,
			<6375 5535 5184 5052 5020 5013>,
			<6398 5564 5182 5055 5026 5024>,
			<6488 5609 5196 5061 5034 5033>,
			<6604 5670 5214 5069 5046 5043>,
			<6757 5742 5240 5080 5054 5049>,
			<6984 5843 5270 5081 5043 5034>,
			<7534 5981 5292 5068 5029 5024>,
			<8738 6248 5341 5067 5030 5025>,
			<11574 7024 5468 5078 5034 5028>,
			<19934 9685 5817 5095 5045 5040>,
			<19934 9685 5817 5095 5045 5040>,
			<19934 9685 5817 5095 5045 5040>;
	};

};
